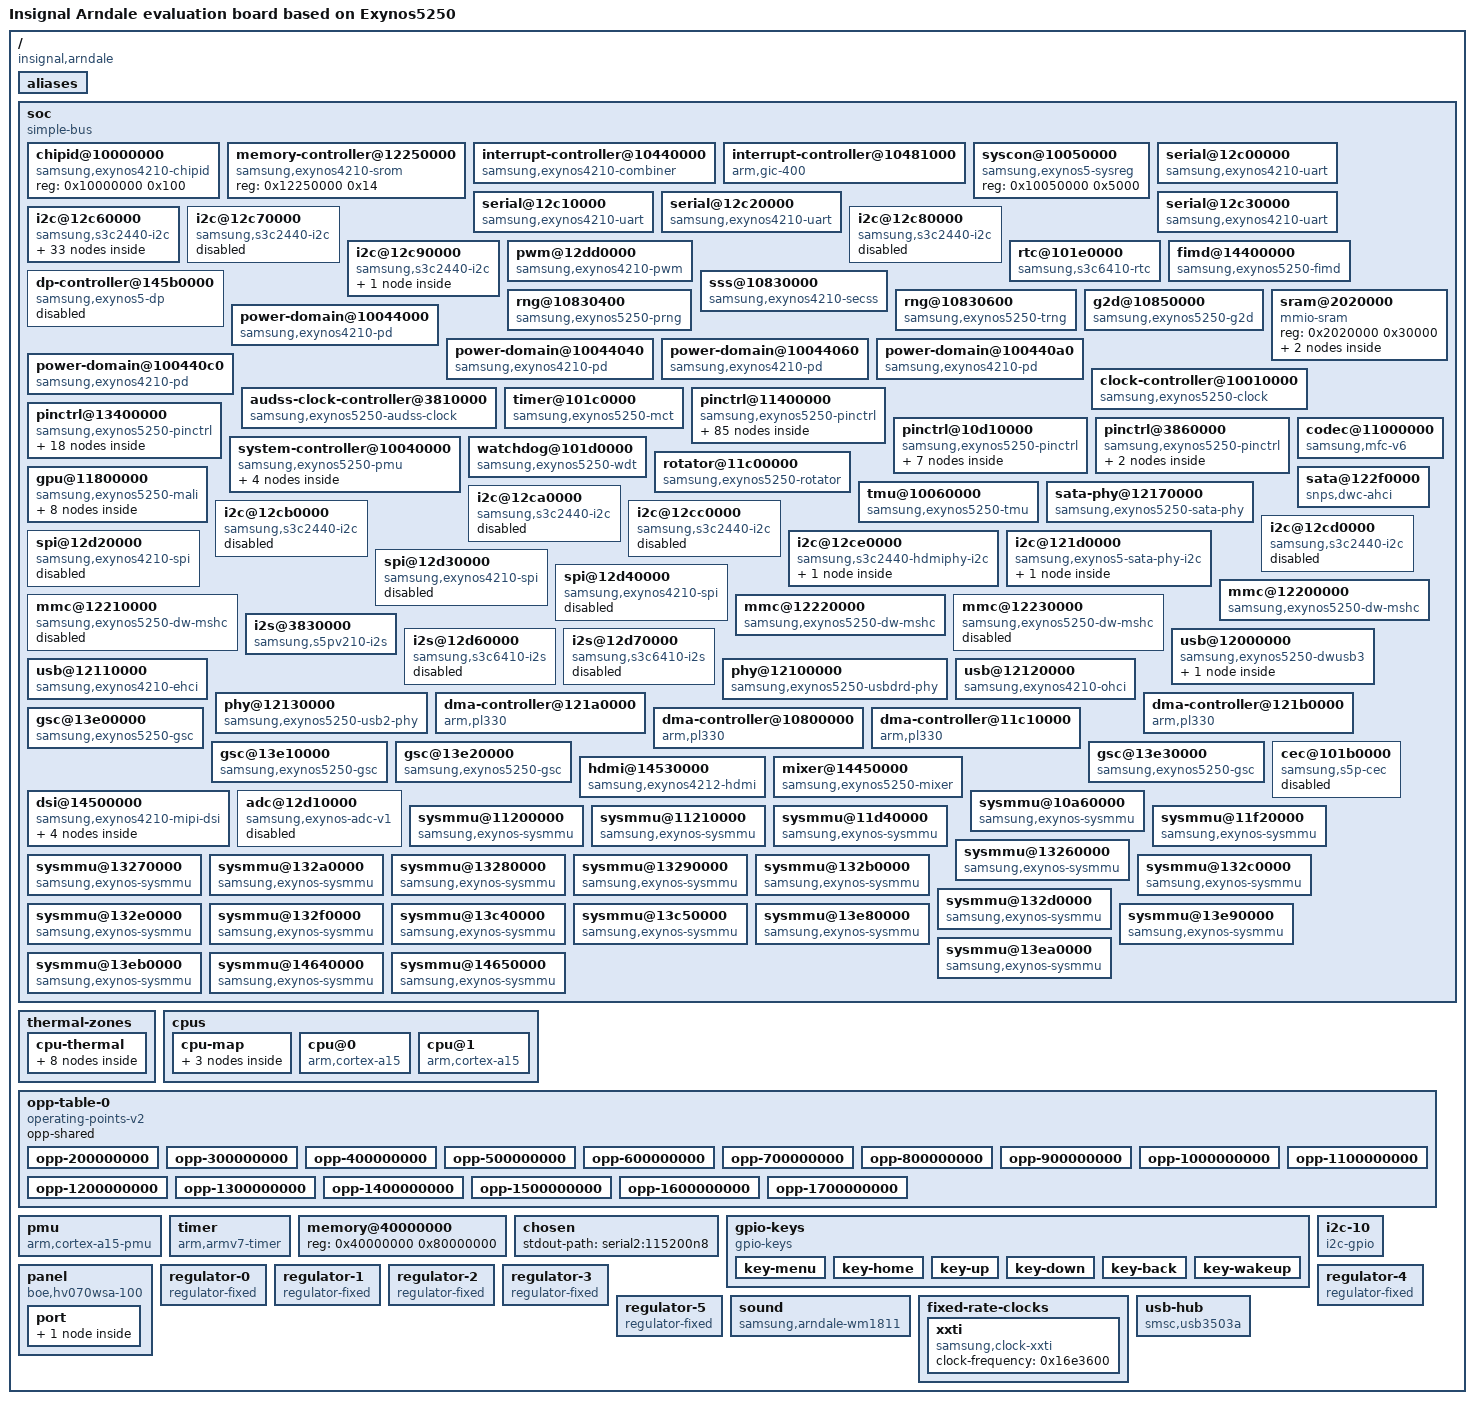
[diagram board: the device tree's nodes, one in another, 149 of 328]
/*
 * Copyright Linux Kernel Team
 *
 * SPDX-License-Identifier: GPL-2.0-only
 *
 * This file is derived from an intermediate build stage of the
 * Linux kernel. The licenses of all input files to this process
 * are compatible with GPL-2.0-only.
 */

/dts-v1/;

/ {
	interrupt-parent = <0x01>;
	#address-cells = <0x01>;
	#size-cells = <0x01>;
	compatible = "insignal,arndale", "samsung,exynos5250", "samsung,exynos5";
	model = "Insignal Arndale evaluation board based on Exynos5250";

	aliases {
		i2c0 = "/soc/i2c@12c60000";
		i2c1 = "/soc/i2c@12c70000";
		i2c2 = "/soc/i2c@12c80000";
		i2c3 = "/soc/i2c@12c90000";
		serial0 = "/soc/serial@12c00000";
		serial1 = "/soc/serial@12c10000";
		serial2 = "/soc/serial@12c20000";
		serial3 = "/soc/serial@12c30000";
		spi0 = "/soc/spi@12d20000";
		spi1 = "/soc/spi@12d30000";
		spi2 = "/soc/spi@12d40000";
		gsc0 = "/soc/gsc@13e00000";
		gsc1 = "/soc/gsc@13e10000";
		gsc2 = "/soc/gsc@13e20000";
		gsc3 = "/soc/gsc@13e30000";
		i2c4 = "/soc/i2c@12ca0000";
		i2c5 = "/soc/i2c@12cb0000";
		i2c6 = "/soc/i2c@12cc0000";
		i2c7 = "/soc/i2c@12cd0000";
		i2c8 = "/soc/i2c@12ce0000";
		i2c9 = "/soc/i2c@121d0000";
		pinctrl0 = "/soc/pinctrl@11400000";
		pinctrl1 = "/soc/pinctrl@13400000";
		pinctrl2 = "/soc/pinctrl@10d10000";
		pinctrl3 = "/soc/pinctrl@3860000";
		mmc0 = "/soc/mmc@12200000";
		mmc1 = "/soc/mmc@12220000";
	};

	soc {
		compatible = "simple-bus";
		#address-cells = <0x01>;
		#size-cells = <0x01>;
		ranges;

		chipid@10000000 {
			compatible = "samsung,exynos4210-chipid";
			reg = <0x10000000 0x100>;
		};

		memory-controller@12250000 {
			compatible = "samsung,exynos4210-srom";
			reg = <0x12250000 0x14>;
		};

		interrupt-controller@10440000 {
			compatible = "samsung,exynos4210-combiner";
			#interrupt-cells = <0x02>;
			interrupt-controller;
			samsung,combiner-nr = <0x20>;
			reg = <0x10440000 0x1000>;
			interrupts = <0x00 0x00 0x04 0x00 0x01 0x04 0x00 0x02 0x04 0x00 0x03 0x04 0x00 0x04 0x04 0x00 0x05 0x04 0x00 0x06 0x04 0x00 0x07 0x04 0x00 0x08 0x04 0x00 0x09 0x04 0x00 0x0a 0x04 0x00 0x0b 0x04 0x00 0x0c 0x04 0x00 0x0d 0x04 0x00 0x0e 0x04 0x00 0x0f 0x04 0x00 0x10 0x04 0x00 0x11 0x04 0x00 0x12 0x04 0x00 0x13 0x04 0x00 0x14 0x04 0x00 0x15 0x04 0x00 0x16 0x04 0x00 0x17 0x04 0x00 0x18 0x04 0x00 0x19 0x04 0x00 0x1a 0x04 0x00 0x1b 0x04 0x00 0x1c 0x04 0x00 0x1d 0x04 0x00 0x1e 0x04 0x00 0x1f 0x04>;
			phandle = <0x15>;
		};

		interrupt-controller@10481000 {
			compatible = "arm,gic-400", "arm,cortex-a15-gic";
			#interrupt-cells = <0x03>;
			interrupt-controller;
			reg = <0x10481000 0x1000 0x10482000 0x2000 0x10484000 0x2000 0x10486000 0x2000>;
			interrupts = <0x01 0x09 0xf04>;
			phandle = <0x01>;
		};

		syscon@10050000 {
			compatible = "samsung,exynos5-sysreg", "syscon";
			reg = <0x10050000 0x5000>;
			phandle = <0x05>;
		};

		serial@12c00000 {
			compatible = "samsung,exynos4210-uart";
			reg = <0x12c00000 0x100>;
			interrupts = <0x00 0x33 0x04>;
			clocks = <0x02 0x121 0x02 0x92>;
			clock-names = "uart", "clk_uart_baud0";
			dmas = <0x03 0x0d 0x03 0x0e>;
			dma-names = "rx", "tx";
		};

		serial@12c10000 {
			compatible = "samsung,exynos4210-uart";
			reg = <0x12c10000 0x100>;
			interrupts = <0x00 0x34 0x04>;
			clocks = <0x02 0x122 0x02 0x93>;
			clock-names = "uart", "clk_uart_baud0";
			dmas = <0x04 0x0f 0x04 0x10>;
			dma-names = "rx", "tx";
		};

		serial@12c20000 {
			compatible = "samsung,exynos4210-uart";
			reg = <0x12c20000 0x100>;
			interrupts = <0x00 0x35 0x04>;
			clocks = <0x02 0x123 0x02 0x94>;
			clock-names = "uart", "clk_uart_baud0";
			dmas = <0x03 0x0f 0x03 0x10>;
			dma-names = "rx", "tx";
		};

		serial@12c30000 {
			compatible = "samsung,exynos4210-uart";
			reg = <0x12c30000 0x100>;
			interrupts = <0x00 0x36 0x04>;
			clocks = <0x02 0x124 0x02 0x95>;
			clock-names = "uart", "clk_uart_baud0";
			dmas = <0x04 0x11 0x04 0x12>;
			dma-names = "rx", "tx";
		};

		i2c@12c60000 {
			compatible = "samsung,s3c2440-i2c";
			reg = <0x12c60000 0x100>;
			interrupts = <0x00 0x38 0x04>;
			#address-cells = <0x01>;
			#size-cells = <0x00>;
			samsung,sysreg-phandle = <0x05>;
			status = "okay";
			clocks = <0x02 0x126>;
			clock-names = "i2c";
			pinctrl-names = "default";
			pinctrl-0 = <0x06>;
			samsung,i2c-sda-delay = <0x64>;
			samsung,i2c-max-bus-freq = <0x4e20>;
			samsung,i2c-slave-addr = <0x66>;

			pmic@66 {
				compatible = "samsung,s5m8767-pmic";
				reg = <0x66>;
				interrupt-parent = <0x07>;
				interrupts = <0x02 0x08>;
				pinctrl-names = "default";
				pinctrl-0 = <0x08>;
				wakeup-source;
				vinb1-supply = <0x09>;
				vinb2-supply = <0x09>;
				vinb3-supply = <0x09>;
				vinb4-supply = <0x09>;
				vinb5-supply = <0x09>;
				vinb6-supply = <0x09>;
				vinb7-supply = <0x09>;
				vinb8-supply = <0x09>;
				vinb9-supply = <0x09>;
				vinl1-supply = <0x0a>;
				vinl2-supply = <0x0a>;
				vinl3-supply = <0x0a>;
				vinl4-supply = <0x09>;
				vinl5-supply = <0x09>;
				vinl6-supply = <0x09>;
				vinl7-supply = <0x09>;
				vinl8-supply = <0x0b>;
				vinl9-supply = <0x0b>;
				s5m8767,pmic-buck-dvs-gpios = <0x0c 0x00 0x00 0x0c 0x01 0x00 0x0c 0x02 0x00>;
				s5m8767,pmic-buck-ds-gpios = <0x0d 0x03 0x00 0x0d 0x04 0x00 0x0d 0x05 0x00>;

				clocks {
					compatible = "samsung,s5m8767-clk";
					#clock-cells = <0x01>;
					clock-output-names = "s5m8767_ap", "unused1", "unused2";
					phandle = <0x13>;
				};

				regulators {

					LDO1 {
						regulator-name = "VDD_ALIVE_1.0V";
						regulator-min-microvolt = <0x10c8e0>;
						regulator-max-microvolt = <0x10c8e0>;
						regulator-always-on;
						regulator-boot-on;
						op_mode = <0x01>;
					};

					LDO2 {
						regulator-name = "VDD_28IO_DP_1.35V";
						regulator-min-microvolt = <0x124f80>;
						regulator-max-microvolt = <0x124f80>;
						regulator-always-on;
						regulator-boot-on;
						op_mode = <0x01>;
					};

					LDO3 {
						regulator-name = "VDD_COMMON1_1.8V";
						regulator-min-microvolt = <0x1b7740>;
						regulator-max-microvolt = <0x1b7740>;
						regulator-always-on;
						regulator-boot-on;
						op_mode = <0x01>;
					};

					LDO4 {
						regulator-name = "VDD_IOPERI_1.8V";
						regulator-min-microvolt = <0x1b7740>;
						regulator-max-microvolt = <0x1b7740>;
						regulator-always-on;
						op_mode = <0x01>;
					};

					LDO5 {
						regulator-name = "VDD_EXT_1.8V";
						regulator-min-microvolt = <0x1b7740>;
						regulator-max-microvolt = <0x1b7740>;
						regulator-always-on;
						regulator-boot-on;
						op_mode = <0x01>;
					};

					LDO6 {
						regulator-name = "VDD_MPLL_1.1V";
						regulator-min-microvolt = <0x10c8e0>;
						regulator-max-microvolt = <0x10c8e0>;
						regulator-always-on;
						regulator-boot-on;
						op_mode = <0x01>;
					};

					LDO7 {
						regulator-name = "VDD_XPLL_1.1V";
						regulator-min-microvolt = <0x10c8e0>;
						regulator-max-microvolt = <0x10c8e0>;
						regulator-always-on;
						regulator-boot-on;
						op_mode = <0x01>;
					};

					LDO8 {
						regulator-name = "VDD_COMMON2_1.0V";
						regulator-min-microvolt = <0xf4240>;
						regulator-max-microvolt = <0xf4240>;
						regulator-always-on;
						regulator-boot-on;
						op_mode = <0x01>;
						phandle = <0x45>;
					};

					LDO9 {
						regulator-name = "VDD_33ON_3.0V";
						regulator-min-microvolt = <0x2dc6c0>;
						regulator-max-microvolt = <0x2dc6c0>;
						op_mode = <0x01>;
					};

					LDO10 {
						regulator-name = "VDD_COMMON3_1.8V";
						regulator-min-microvolt = <0x1b7740>;
						regulator-max-microvolt = <0x1b7740>;
						regulator-always-on;
						regulator-boot-on;
						op_mode = <0x01>;
						phandle = <0x44>;
					};

					LDO11 {
						regulator-name = "VDD_ABB2_1.8V";
						regulator-min-microvolt = <0x1b7740>;
						regulator-max-microvolt = <0x1b7740>;
						regulator-always-on;
						regulator-boot-on;
						op_mode = <0x01>;
					};

					LDO12 {
						regulator-name = "VDD_USB_3.0V";
						regulator-min-microvolt = <0x2dc6c0>;
						regulator-max-microvolt = <0x2dc6c0>;
						regulator-always-on;
						regulator-boot-on;
						op_mode = <0x01>;
						phandle = <0x39>;
					};

					LDO13 {
						regulator-name = "VDDQ_C2C_W_1.8V";
						regulator-min-microvolt = <0x1b7740>;
						regulator-max-microvolt = <0x1b7740>;
						regulator-always-on;
						regulator-boot-on;
						op_mode = <0x01>;
					};

					LDO14 {
						regulator-name = "VDD18_ABB0_3_1.8V";
						regulator-min-microvolt = <0x1b7740>;
						regulator-max-microvolt = <0x1b7740>;
						regulator-always-on;
						regulator-boot-on;
						op_mode = <0x01>;
					};

					LDO15 {
						regulator-name = "VDD10_COMMON4_1.0V";
						regulator-min-microvolt = <0xf4240>;
						regulator-max-microvolt = <0xf4240>;
						regulator-always-on;
						regulator-boot-on;
						op_mode = <0x01>;
						phandle = <0x38>;
					};

					LDO16 {
						regulator-name = "VDD18_HSIC_1.8V";
						regulator-min-microvolt = <0x1b7740>;
						regulator-max-microvolt = <0x1b7740>;
						regulator-always-on;
						regulator-boot-on;
						op_mode = <0x01>;
					};

					LDO17 {
						regulator-name = "VDDQ_MMC2_3_2.8V";
						regulator-min-microvolt = <0x2ab980>;
						regulator-max-microvolt = <0x2ab980>;
						regulator-always-on;
						regulator-boot-on;
						op_mode = <0x01>;
					};

					LDO18 {
						regulator-name = "VDD_33ON_2.8V";
						regulator-min-microvolt = <0x2ab980>;
						regulator-max-microvolt = <0x2ab980>;
						op_mode = <0x01>;
					};

					LDO22 {
						regulator-name = "EXT_33_OFF";
						regulator-min-microvolt = <0x325aa0>;
						regulator-max-microvolt = <0x325aa0>;
						op_mode = <0x01>;
					};

					LDO23 {
						regulator-name = "EXT_28_OFF";
						regulator-min-microvolt = <0x2ab980>;
						regulator-max-microvolt = <0x2ab980>;
						op_mode = <0x01>;
					};

					LDO25 {
						regulator-name = "PVDD_LDO25";
						regulator-min-microvolt = <0x124f80>;
						regulator-max-microvolt = <0x124f80>;
						op_mode = <0x01>;
					};

					LDO26 {
						regulator-name = "EXT_18_OFF";
						regulator-min-microvolt = <0x1b7740>;
						regulator-max-microvolt = <0x1b7740>;
						op_mode = <0x01>;
					};

					BUCK1 {
						regulator-name = "VDD_MIF";
						regulator-min-microvolt = <0xe7ef0>;
						regulator-max-microvolt = <0x124f80>;
						regulator-always-on;
						regulator-boot-on;
						op_mode = <0x01>;
					};

					BUCK2 {
						regulator-name = "VDD_ARM";
						regulator-min-microvolt = <0xdec74>;
						regulator-max-microvolt = <0x13d620>;
						regulator-always-on;
						regulator-boot-on;
						op_mode = <0x01>;
						phandle = <0x54>;
					};

					BUCK3 {
						regulator-name = "VDD_INT";
						regulator-min-microvolt = <0xdbba0>;
						regulator-max-microvolt = <0x124f80>;
						regulator-always-on;
						regulator-boot-on;
						op_mode = <0x01>;
					};

					BUCK4 {
						regulator-name = "VDD_G3D";
						regulator-min-microvolt = <0xcf850>;
						regulator-max-microvolt = <0x13d620>;
						regulator-always-on;
						regulator-boot-on;
						op_mode = <0x01>;
						phandle = <0x22>;
					};

					BUCK5 {
						regulator-name = "VDD_MEM_1.35V";
						regulator-min-microvolt = <0xb71b0>;
						regulator-max-microvolt = <0x14acf8>;
						regulator-always-on;
						regulator-boot-on;
						op_mode = <0x01>;
					};

					BUCK7 {
						regulator-name = "PVDD_BUCK7";
						regulator-always-on;
						op_mode = <0x01>;
						phandle = <0x0a>;
					};

					BUCK8 {
						regulator-name = "PVDD_BUCK8";
						regulator-always-on;
						op_mode = <0x01>;
						phandle = <0x0b>;
					};

					BUCK9 {
						regulator-name = "VDD_33_OFF_EXT1";
						regulator-min-microvolt = <0xb71b0>;
						regulator-max-microvolt = <0x2dc6c0>;
						op_mode = <0x01>;
					};
				};
			};
		};

		i2c@12c70000 {
			compatible = "samsung,s3c2440-i2c";
			reg = <0x12c70000 0x100>;
			interrupts = <0x00 0x39 0x04>;
			#address-cells = <0x01>;
			#size-cells = <0x00>;
			samsung,sysreg-phandle = <0x05>;
			status = "disabled";
			clocks = <0x02 0x127>;
			clock-names = "i2c";
			pinctrl-names = "default";
			pinctrl-0 = <0x0e>;
		};

		i2c@12c80000 {
			compatible = "samsung,s3c2440-i2c";
			reg = <0x12c80000 0x100>;
			interrupts = <0x00 0x3a 0x04>;
			#address-cells = <0x01>;
			#size-cells = <0x00>;
			samsung,sysreg-phandle = <0x05>;
			status = "disabled";
			clocks = <0x02 0x128>;
			clock-names = "i2c";
			pinctrl-names = "default";
			pinctrl-0 = <0x0f>;
		};

		i2c@12c90000 {
			compatible = "samsung,s3c2440-i2c";
			reg = <0x12c90000 0x100>;
			interrupts = <0x00 0x3b 0x04>;
			#address-cells = <0x01>;
			#size-cells = <0x00>;
			samsung,sysreg-phandle = <0x05>;
			status = "okay";
			clocks = <0x02 0x129>;
			clock-names = "i2c";
			pinctrl-names = "default";
			pinctrl-0 = <0x10>;

			audio-codec@1a {
				compatible = "wlf,wm1811";
				reg = <0x1a>;
				clocks = <0x11 0x00>;
				clock-names = "MCLK1";
				AVDD2-supply = <0x09>;
				CPVDD-supply = <0x09>;
				DBVDD1-supply = <0x09>;
				DBVDD2-supply = <0x09>;
				DBVDD3-supply = <0x09>;
				LDO1VDD-supply = <0x09>;
				SPKVDD1-supply = <0x09>;
				SPKVDD2-supply = <0x09>;
				wlf,ldo1ena-gpios = <0x12 0x00 0x00>;
				wlf,ldo2ena-gpios = <0x12 0x01 0x00>;
				phandle = <0x59>;
			};
		};

		pwm@12dd0000 {
			compatible = "samsung,exynos4210-pwm";
			reg = <0x12dd0000 0x100>;
			interrupts = <0x00 0x24 0x04 0x00 0x25 0x04 0x00 0x26 0x04 0x00 0x27 0x04 0x00 0x28 0x04>;
			samsung,pwm-outputs = <0x00 0x01 0x02 0x03>;
			#pwm-cells = <0x03>;
			clocks = <0x02 0x137>;
			clock-names = "timers";
		};

		rtc@101e0000 {
			compatible = "samsung,s3c6410-rtc";
			reg = <0x101e0000 0x100>;
			interrupts = <0x00 0x2b 0x04 0x00 0x2c 0x04>;
			status = "okay";
			clocks = <0x02 0x151 0x13 0x00>;
			clock-names = "rtc", "rtc_src";
			interrupt-parent = <0x14>;
		};

		fimd@14400000 {
			compatible = "samsung,exynos5250-fimd";
			interrupt-parent = <0x15>;
			reg = <0x14400000 0x40000>;
			interrupt-names = "fifo", "vsync", "lcd_sys";
			interrupts = <0x12 0x04 0x12 0x05 0x12 0x06>;
			samsung,sysreg = <0x05>;
			status = "okay";
			power-domains = <0x16>;
			clocks = <0x02 0x85 0x02 0x153>;
			clock-names = "sclk_fimd", "fimd";
			iommus = <0x17>;
		};

		dp-controller@145b0000 {
			compatible = "samsung,exynos5-dp";
			reg = <0x145b0000 0x1000>;
			interrupts = <0x0a 0x03>;
			interrupt-parent = <0x15>;
			status = "disabled";
			power-domains = <0x16>;
			clocks = <0x02 0x156>;
			clock-names = "dp";
			phys = <0x18>;
			phy-names = "dp";
		};

		sss@10830000 {
			compatible = "samsung,exynos4210-secss";
			reg = <0x10830000 0x300>;
			interrupts = <0x00 0x70 0x04>;
			clocks = <0x02 0x15c>;
			clock-names = "secss";
		};

		rng@10830400 {
			compatible = "samsung,exynos5250-prng";
			reg = <0x10830400 0x200>;
			clocks = <0x02 0x15c>;
			clock-names = "secss";
		};

		rng@10830600 {
			compatible = "samsung,exynos5250-trng";
			reg = <0x10830600 0x100>;
			clocks = <0x02 0x15c>;
			clock-names = "secss";
		};

		g2d@10850000 {
			compatible = "samsung,exynos5250-g2d";
			reg = <0x10850000 0x1000>;
			interrupts = <0x00 0x5b 0x04>;
			status = "okay";
			iommus = <0x19>;
			clocks = <0x02 0x159>;
			clock-names = "fimg2d";
		};

		sram@2020000 {
			compatible = "mmio-sram";
			reg = <0x2020000 0x30000>;
			#address-cells = <0x01>;
			#size-cells = <0x01>;
			ranges = <0x00 0x2020000 0x30000>;

			smp-sram@0 {
				compatible = "samsung,exynos4210-sysram";
				reg = <0x00 0x1000>;
			};

			smp-sram@2f000 {
				compatible = "samsung,exynos4210-sysram-ns";
				reg = <0x2f000 0x1000>;
			};
		};

		power-domain@10044000 {
			compatible = "samsung,exynos4210-pd";
			reg = <0x10044000 0x20>;
			#power-domain-cells = <0x00>;
			label = "GSC";
			phandle = <0x3c>;
		};

		power-domain@10044040 {
			compatible = "samsung,exynos4210-pd";
			reg = <0x10044040 0x20>;
			#power-domain-cells = <0x00>;
			label = "MFC";
			phandle = <0x1c>;
		};

		power-domain@10044060 {
			compatible = "samsung,exynos4210-pd";
			reg = <0x10044060 0x20>;
			#power-domain-cells = <0x00>;
			label = "G3D";
			phandle = <0x21>;
		};

		power-domain@100440a0 {
			compatible = "samsung,exynos4210-pd";
			reg = <0x100440a0 0x20>;
			#power-domain-cells = <0x00>;
			label = "DISP1";
			phandle = <0x16>;
		};

		power-domain@100440c0 {
			compatible = "samsung,exynos4210-pd";
			reg = <0x100440c0 0x20>;
			#power-domain-cells = <0x00>;
			label = "MAU";
			phandle = <0x1a>;
		};

		clock-controller@10010000 {
			compatible = "samsung,exynos5250-clock";
			reg = <0x10010000 0x30000>;
			#clock-cells = <0x01>;
			assigned-clocks = <0x02 0x07>;
			assigned-clock-rates = <0x2ee0000>;
			phandle = <0x02>;
		};

		audss-clock-controller@3810000 {
			compatible = "samsung,exynos5250-audss-clock";
			reg = <0x3810000 0x0c>;
			#clock-cells = <0x01>;
			clocks = <0x02 0x01 0x02 0x07 0x02 0x8a 0x02 0xa0>;
			clock-names = "pll_ref", "pll_in", "sclk_audio", "sclk_pcm_in";
			power-domains = <0x1a>;
			assigned-clocks = <0x1b 0x00>;
			assigned-clock-parents = <0x02 0x07>;
			phandle = <0x1b>;
		};

		timer@101c0000 {
			compatible = "samsung,exynos5250-mct", "samsung,exynos4210-mct";
			reg = <0x101c0000 0x800>;
			clocks = <0x02 0x01 0x02 0x14f>;
			clock-names = "fin_pll", "mct";
			interrupts-extended = <0x15 0x17 0x03 0x15 0x17 0x04 0x15 0x19 0x02 0x15 0x19 0x03 0x01 0x00 0x78 0x04 0x01 0x00 0x79 0x04>;
		};

		pinctrl@11400000 {
			compatible = "samsung,exynos5250-pinctrl";
			reg = <0x11400000 0x1000>;
			interrupts = <0x00 0x2e 0x04>;

			wakeup-interrupt-controller {
				compatible = "samsung,exynos4210-wakeup-eint";
				interrupt-parent = <0x01>;
				interrupts = <0x00 0x20 0x04>;
			};

			gpa0-gpio-bank {
				gpio-controller;
				#gpio-cells = <0x02>;
				interrupt-controller;
				#interrupt-cells = <0x02>;
				phandle = <0x57>;
			};

			gpa1-gpio-bank {
				gpio-controller;
				#gpio-cells = <0x02>;
				interrupt-controller;
				#interrupt-cells = <0x02>;
			};

			gpa2-gpio-bank {
				gpio-controller;
				#gpio-cells = <0x02>;
				interrupt-controller;
				#interrupt-cells = <0x02>;
			};

			gpb0-gpio-bank {
				gpio-controller;
				#gpio-cells = <0x02>;
				interrupt-controller;
				#interrupt-cells = <0x02>;
				phandle = <0x12>;
			};

			gpb1-gpio-bank {
				gpio-controller;
				#gpio-cells = <0x02>;
				interrupt-controller;
				#interrupt-cells = <0x02>;
			};

			gpb2-gpio-bank {
				gpio-controller;
				#gpio-cells = <0x02>;
				interrupt-controller;
				#interrupt-cells = <0x02>;
			};

			gpb3-gpio-bank {
				gpio-controller;
				#gpio-cells = <0x02>;
				interrupt-controller;
				#interrupt-cells = <0x02>;
			};

			gpc0-gpio-bank {
				gpio-controller;
				#gpio-cells = <0x02>;
				interrupt-controller;
				#interrupt-cells = <0x02>;
			};

			gpc1-gpio-bank {
				gpio-controller;
				#gpio-cells = <0x02>;
				interrupt-controller;
				#interrupt-cells = <0x02>;
			};

			gpc2-gpio-bank {
				gpio-controller;
				#gpio-cells = <0x02>;
				interrupt-controller;
				#interrupt-cells = <0x02>;
			};

			gpc3-gpio-bank {
				gpio-controller;
				#gpio-cells = <0x02>;
				interrupt-controller;
				#interrupt-cells = <0x02>;
			};

			gpd0-gpio-bank {
				gpio-controller;
				#gpio-cells = <0x02>;
				interrupt-controller;
				#interrupt-cells = <0x02>;
			};

			gpd1-gpio-bank {
				gpio-controller;
				#gpio-cells = <0x02>;
				interrupt-controller;
				#interrupt-cells = <0x02>;
				phandle = <0x0c>;
			};

			gpy0-gpio-bank {
				gpio-controller;
				#gpio-cells = <0x02>;
			};

			gpy1-gpio-bank {
				gpio-controller;
				#gpio-cells = <0x02>;
			};

			gpy2-gpio-bank {
				gpio-controller;
				#gpio-cells = <0x02>;
			};

			gpy3-gpio-bank {
				gpio-controller;
				#gpio-cells = <0x02>;
			};

			gpy4-gpio-bank {
				gpio-controller;
				#gpio-cells = <0x02>;
			};

			gpy5-gpio-bank {
				gpio-controller;
				#gpio-cells = <0x02>;
			};

			gpy6-gpio-bank {
				gpio-controller;
				#gpio-cells = <0x02>;
			};

			gpc4-gpio-bank {
				gpio-controller;
				#gpio-cells = <0x02>;
				interrupt-controller;
				#interrupt-cells = <0x02>;
			};

			gpx0-gpio-bank {
				gpio-controller;
				#gpio-cells = <0x02>;
				interrupt-controller;
				interrupt-parent = <0x15>;
				#interrupt-cells = <0x02>;
				interrupts = <0x17 0x00 0x18 0x00 0x19 0x00 0x19 0x01 0x1a 0x00 0x1a 0x01 0x1b 0x00 0x1b 0x01>;
			};

			gpx1-gpio-bank {
				gpio-controller;
				#gpio-cells = <0x02>;
				interrupt-controller;
				interrupt-parent = <0x15>;
				#interrupt-cells = <0x02>;
				interrupts = <0x1c 0x00 0x1c 0x01 0x1d 0x00 0x1d 0x01 0x1e 0x00 0x1e 0x01 0x1f 0x00 0x1f 0x01>;
				phandle = <0x55>;
			};

			gpx2-gpio-bank {
				gpio-controller;
				#gpio-cells = <0x02>;
				interrupt-controller;
				#interrupt-cells = <0x02>;
				phandle = <0x0d>;
			};

			gpx3-gpio-bank {
				gpio-controller;
				#gpio-cells = <0x02>;
				interrupt-controller;
				#interrupt-cells = <0x02>;
				phandle = <0x07>;
			};

			uart0-data-pins {
				samsung,pins = "gpa0-0", "gpa0-1";
				samsung,pin-function = <0x02>;
				samsung,pin-pud = <0x00>;
				samsung,pin-drv = <0x00>;
			};

			uart0-fctl-pins {
				samsung,pins = "gpa0-2", "gpa0-3";
				samsung,pin-function = <0x02>;
				samsung,pin-pud = <0x00>;
				samsung,pin-drv = <0x00>;
			};

			i2c2-bus-pins {
				samsung,pins = "gpa0-6", "gpa0-7";
				samsung,pin-function = <0x03>;
				samsung,pin-pud = <0x03>;
				samsung,pin-drv = <0x00>;
				phandle = <0x0f>;
			};

			i2c2-hs-bus-pins {
				samsung,pins = "gpa0-6", "gpa0-7";
				samsung,pin-function = <0x04>;
				samsung,pin-pud = <0x03>;
				samsung,pin-drv = <0x00>;
			};

			i2c2-gpio-bus-pins {
				samsung,pins = "gpa0-6", "gpa0-7";
				samsung,pin-pud = <0x00>;
				samsung,pin-drv = <0x00>;
				phandle = <0x56>;
			};

			uart2-data-pins {
				samsung,pins = "gpa1-0", "gpa1-1";
				samsung,pin-function = <0x02>;
				samsung,pin-pud = <0x00>;
				samsung,pin-drv = <0x00>;
			};

			uart2-fctl-pins {
				samsung,pins = "gpa1-2", "gpa1-3";
				samsung,pin-function = <0x02>;
				samsung,pin-pud = <0x00>;
				samsung,pin-drv = <0x00>;
			};

			i2c3-bus-pins {
				samsung,pins = "gpa1-2", "gpa1-3";
				samsung,pin-function = <0x03>;
				samsung,pin-pud = <0x03>;
				samsung,pin-drv = <0x00>;
				phandle = <0x10>;
			};

			i2c3-hs-bus-pins {
				samsung,pins = "gpa1-2", "gpa1-3";
				samsung,pin-function = <0x04>;
				samsung,pin-pud = <0x03>;
				samsung,pin-drv = <0x00>;
			};

			uart3-data-pins {
				samsung,pins = "gpa1-4", "gpa1-5";
				samsung,pin-function = <0x02>;
				samsung,pin-pud = <0x00>;
				samsung,pin-drv = <0x00>;
			};

			spi0-bus-pins {
				samsung,pins = "gpa2-0", "gpa2-2", "gpa2-3";
				samsung,pin-function = <0x02>;
				samsung,pin-pud = <0x03>;
				samsung,pin-drv = <0x00>;
				phandle = <0x29>;
			};

			i2c4-bus-pins {
				samsung,pins = "gpa2-0", "gpa2-1";
				samsung,pin-function = <0x03>;
				samsung,pin-pud = <0x03>;
				samsung,pin-drv = <0x00>;
				phandle = <0x25>;
			};

			i2c5-bus-pins {
				samsung,pins = "gpa2-2", "gpa2-3";
				samsung,pin-function = <0x03>;
				samsung,pin-pud = <0x03>;
				samsung,pin-drv = <0x00>;
				phandle = <0x26>;
			};

			spi1-bus-pins {
				samsung,pins = "gpa2-4", "gpa2-6", "gpa2-7";
				samsung,pin-function = <0x02>;
				samsung,pin-pud = <0x03>;
				samsung,pin-drv = <0x00>;
				phandle = <0x2a>;
			};

			i2s1-bus-pins {
				samsung,pins = "gpb0-0", "gpb0-1", "gpb0-2", "gpb0-3", "gpb0-4";
				samsung,pin-function = <0x02>;
				samsung,pin-pud = <0x00>;
				samsung,pin-drv = <0x00>;
				phandle = <0x36>;
			};

			pcm1-bus-pins {
				samsung,pins = "gpb0-0", "gpb0-1", "gpb0-2", "gpb0-3", "gpb0-4";
				samsung,pin-function = <0x03>;
				samsung,pin-pud = <0x00>;
				samsung,pin-drv = <0x00>;
			};

			ac97-bus-pins {
				samsung,pins = "gpb0-0", "gpb0-1", "gpb0-2", "gpb0-3", "gpb0-4";
				samsung,pin-function = <0x04>;
				samsung,pin-pud = <0x00>;
				samsung,pin-drv = <0x00>;
			};

			i2s2-bus-pins {
				samsung,pins = "gpb1-0", "gpb1-1", "gpb1-2", "gpb1-3", "gpb1-4";
				samsung,pin-function = <0x02>;
				samsung,pin-pud = <0x00>;
				samsung,pin-drv = <0x00>;
				phandle = <0x37>;
			};

			pcm2-bus-pins {
				samsung,pins = "gpb1-0", "gpb1-1", "gpb1-2", "gpb1-3", "gpb1-4";
				samsung,pin-function = <0x03>;
				samsung,pin-pud = <0x00>;
				samsung,pin-drv = <0x00>;
			};

			spdif-bus-pins {
				samsung,pins = "gpb1-0", "gpb1-1";
				samsung,pin-function = <0x04>;
				samsung,pin-pud = <0x00>;
				samsung,pin-drv = <0x00>;
			};

			spi2-bus-pins {
				samsung,pins = "gpb1-1", "gpb1-3", "gpb1-4";
				samsung,pin-function = <0x05>;
				samsung,pin-pud = <0x03>;
				samsung,pin-drv = <0x00>;
				phandle = <0x2b>;
			};

			i2c6-bus-pins {
				samsung,pins = "gpb1-3", "gpb1-4";
				samsung,pin-function = <0x04>;
				samsung,pin-pud = <0x03>;
				samsung,pin-drv = <0x00>;
				phandle = <0x27>;
			};

			pwm0-out-pins {
				samsung,pins = "gpb2-0";
				samsung,pin-function = <0x02>;
				samsung,pin-pud = <0x00>;
				samsung,pin-drv = <0x00>;
			};

			pwm1-out-pins {
				samsung,pins = "gpb2-1";
				samsung,pin-function = <0x02>;
				samsung,pin-pud = <0x00>;
				samsung,pin-drv = <0x00>;
			};

			pwm2-out-pins {
				samsung,pins = "gpb2-2";
				samsung,pin-function = <0x02>;
				samsung,pin-pud = <0x00>;
				samsung,pin-drv = <0x00>;
			};

			pwm3-out-pins {
				samsung,pins = "gpb2-3";
				samsung,pin-function = <0x02>;
				samsung,pin-pud = <0x00>;
				samsung,pin-drv = <0x00>;
			};

			i2c7-bus-pins {
				samsung,pins = "gpb2-2", "gpb2-3";
				samsung,pin-function = <0x03>;
				samsung,pin-pud = <0x03>;
				samsung,pin-drv = <0x00>;
				phandle = <0x28>;
			};

			i2c0-bus-pins {
				samsung,pins = "gpb3-0", "gpb3-1";
				samsung,pin-function = <0x02>;
				samsung,pin-pud = <0x03>;
				samsung,pin-drv = <0x00>;
				phandle = <0x06>;
			};

			i2c1-bus-pins {
				samsung,pins = "gpb3-2", "gpb3-3";
				samsung,pin-function = <0x02>;
				samsung,pin-pud = <0x03>;
				samsung,pin-drv = <0x00>;
				phandle = <0x0e>;
			};

			i2c0-hs-bus-pins {
				samsung,pins = "gpb3-0", "gpb3-1";
				samsung,pin-function = <0x04>;
				samsung,pin-pud = <0x03>;
				samsung,pin-drv = <0x00>;
			};

			i2c1-hs-bus-pins {
				samsung,pins = "gpb3-2", "gpb3-3";
				samsung,pin-function = <0x04>;
				samsung,pin-pud = <0x03>;
				samsung,pin-drv = <0x00>;
			};

			sd0-clk-pins {
				samsung,pins = "gpc0-0";
				samsung,pin-function = <0x02>;
				samsung,pin-pud = <0x00>;
				samsung,pin-drv = <0x03>;
				phandle = <0x2d>;
			};

			sd0-cmd-pins {
				samsung,pins = "gpc0-1";
				samsung,pin-function = <0x02>;
				samsung,pin-pud = <0x00>;
				samsung,pin-drv = <0x03>;
				phandle = <0x2e>;
			};

			sd0-cd-pins {
				samsung,pins = "gpc0-2";
				samsung,pin-function = <0x02>;
				samsung,pin-pud = <0x03>;
				samsung,pin-drv = <0x03>;
			};

			sd0-bus-width1-pins {
				samsung,pins = "gpc0-3";
				samsung,pin-function = <0x02>;
				samsung,pin-pud = <0x03>;
				samsung,pin-drv = <0x03>;
			};

			sd0-bus-width4-pins {
				samsung,pins = "gpc0-3", "gpc0-4", "gpc0-5", "gpc0-6";
				samsung,pin-function = <0x02>;
				samsung,pin-pud = <0x03>;
				samsung,pin-drv = <0x03>;
				phandle = <0x2f>;
			};

			sd0-bus-width8-pins {
				samsung,pins = "gpc1-0", "gpc1-1", "gpc1-2", "gpc1-3";
				samsung,pin-function = <0x02>;
				samsung,pin-pud = <0x03>;
				samsung,pin-drv = <0x03>;
				phandle = <0x30>;
			};

			sd1-clk-pins {
				samsung,pins = "gpc2-0";
				samsung,pin-function = <0x02>;
				samsung,pin-pud = <0x00>;
				samsung,pin-drv = <0x03>;
			};

			sd1-cmd-pins {
				samsung,pins = "gpc2-1";
				samsung,pin-function = <0x02>;
				samsung,pin-pud = <0x00>;
				samsung,pin-drv = <0x03>;
			};

			sd1-cd-pins {
				samsung,pins = "gpc2-2";
				samsung,pin-function = <0x02>;
				samsung,pin-pud = <0x03>;
				samsung,pin-drv = <0x03>;
			};

			sd1-bus-width1-pins {
				samsung,pins = "gpc2-3";
				samsung,pin-function = <0x02>;
				samsung,pin-pud = <0x03>;
				samsung,pin-drv = <0x03>;
			};

			sd1-bus-width4-pins {
				samsung,pins = "gpc2-3", "gpc2-4", "gpc2-5", "gpc2-6";
				samsung,pin-function = <0x02>;
				samsung,pin-pud = <0x03>;
				samsung,pin-drv = <0x03>;
			};

			sd2-clk-pins {
				samsung,pins = "gpc3-0";
				samsung,pin-function = <0x02>;
				samsung,pin-pud = <0x00>;
				samsung,pin-drv = <0x03>;
				phandle = <0x31>;
			};

			sd2-cmd-pins {
				samsung,pins = "gpc3-1";
				samsung,pin-function = <0x02>;
				samsung,pin-pud = <0x00>;
				samsung,pin-drv = <0x03>;
				phandle = <0x32>;
			};

			sd2-cd-pins {
				samsung,pins = "gpc3-2";
				samsung,pin-function = <0x02>;
				samsung,pin-pud = <0x03>;
				samsung,pin-drv = <0x03>;
				phandle = <0x33>;
			};

			sd2-bus-width1-pins {
				samsung,pins = "gpc3-3";
				samsung,pin-function = <0x02>;
				samsung,pin-pud = <0x03>;
				samsung,pin-drv = <0x03>;
			};

			sd2-bus-width4-pins {
				samsung,pins = "gpc3-3", "gpc3-4", "gpc3-5", "gpc3-6";
				samsung,pin-function = <0x02>;
				samsung,pin-pud = <0x03>;
				samsung,pin-drv = <0x03>;
				phandle = <0x34>;
			};

			sd2-bus-width8-pins {
				samsung,pins = "gpc4-3", "gpc4-4", "gpc4-5", "gpc4-6";
				samsung,pin-function = <0x03>;
				samsung,pin-pud = <0x03>;
				samsung,pin-drv = <0x03>;
			};

			sd3-clk-pins {
				samsung,pins = "gpc4-0";
				samsung,pin-function = <0x02>;
				samsung,pin-pud = <0x00>;
				samsung,pin-drv = <0x03>;
			};

			sd3-cmd-pins {
				samsung,pins = "gpc4-1";
				samsung,pin-function = <0x02>;
				samsung,pin-pud = <0x00>;
				samsung,pin-drv = <0x03>;
			};

			sd3-cd-pins {
				samsung,pins = "gpc4-2";
				samsung,pin-function = <0x02>;
				samsung,pin-pud = <0x03>;
				samsung,pin-drv = <0x03>;
			};

			sd3-bus-width1-pins {
				samsung,pins = "gpc4-3";
				samsung,pin-function = <0x02>;
				samsung,pin-pud = <0x03>;
				samsung,pin-drv = <0x03>;
			};

			sd3-bus-width4-pins {
				samsung,pins = "gpc4-3", "gpc4-4", "gpc4-5", "gpc4-6";
				samsung,pin-function = <0x02>;
				samsung,pin-pud = <0x03>;
				samsung,pin-drv = <0x03>;
			};

			uart1-data-pins {
				samsung,pins = "gpd0-0", "gpd0-1";
				samsung,pin-function = <0x02>;
				samsung,pin-pud = <0x00>;
				samsung,pin-drv = <0x00>;
			};

			uart1-fctl-pins {
				samsung,pins = "gpd0-2", "gpd0-3";
				samsung,pin-function = <0x02>;
				samsung,pin-pud = <0x00>;
				samsung,pin-drv = <0x00>;
			};

			dp-hpd-pins {
				samsung,pins = "gpx0-7";
				samsung,pin-function = <0x03>;
				samsung,pin-pud = <0x00>;
				samsung,pin-drv = <0x00>;
			};

			hdmi-cec-pins {
				samsung,pins = "gpx3-6";
				samsung,pin-function = <0x03>;
				samsung,pin-pud = <0x00>;
				samsung,pin-drv = <0x00>;
				phandle = <0x47>;
			};

			hdmi-hpd-pins {
				samsung,pins = "gpx3-7";
				samsung,pin-pud = <0x00>;
				phandle = <0x42>;
			};

			s5m8767-irq-pins {
				samsung,pins = "gpx3-2";
				samsung,pin-pud = <0x00>;
				phandle = <0x08>;
			};
		};

		pinctrl@13400000 {
			compatible = "samsung,exynos5250-pinctrl";
			reg = <0x13400000 0x1000>;
			interrupts = <0x00 0x2d 0x04>;

			gpe0-gpio-bank {
				gpio-controller;
				#gpio-cells = <0x02>;
				interrupt-controller;
				#interrupt-cells = <0x02>;
			};

			gpe1-gpio-bank {
				gpio-controller;
				#gpio-cells = <0x02>;
				interrupt-controller;
				#interrupt-cells = <0x02>;
			};

			gpf0-gpio-bank {
				gpio-controller;
				#gpio-cells = <0x02>;
				interrupt-controller;
				#interrupt-cells = <0x02>;
			};

			gpf1-gpio-bank {
				gpio-controller;
				#gpio-cells = <0x02>;
				interrupt-controller;
				#interrupt-cells = <0x02>;
			};

			gpg0-gpio-bank {
				gpio-controller;
				#gpio-cells = <0x02>;
				interrupt-controller;
				#interrupt-cells = <0x02>;
			};

			gpg1-gpio-bank {
				gpio-controller;
				#gpio-cells = <0x02>;
				interrupt-controller;
				#interrupt-cells = <0x02>;
			};

			gpg2-gpio-bank {
				gpio-controller;
				#gpio-cells = <0x02>;
				interrupt-controller;
				#interrupt-cells = <0x02>;
			};

			gph0-gpio-bank {
				gpio-controller;
				#gpio-cells = <0x02>;
				interrupt-controller;
				#interrupt-cells = <0x02>;
			};

			gph1-gpio-bank {
				gpio-controller;
				#gpio-cells = <0x02>;
				interrupt-controller;
				#interrupt-cells = <0x02>;
			};

			cam-gpio-a-pins {
				samsung,pins = "gpe0-0", "gpe0-1", "gpe0-2", "gpe0-3", "gpe0-4", "gpe0-5", "gpe0-6", "gpe0-7", "gpe1-0", "gpe1-1";
				samsung,pin-function = <0x02>;
				samsung,pin-pud = <0x00>;
				samsung,pin-drv = <0x00>;
			};

			cam-gpio-b-pins {
				samsung,pins = "gpf0-0", "gpf0-1", "gpf0-2", "gpf0-3", "gpf1-0", "gpf1-1", "gpf1-2", "gpf1-3";
				samsung,pin-function = <0x03>;
				samsung,pin-pud = <0x00>;
				samsung,pin-drv = <0x00>;
			};

			cam-i2c2-bus-pins {
				samsung,pins = "gpe0-6", "gpe1-0";
				samsung,pin-function = <0x04>;
				samsung,pin-pud = <0x03>;
				samsung,pin-drv = <0x00>;
			};

			cam-spi1-bus-pins {
				samsung,pins = "gpe0-4", "gpe0-5", "gpf0-2", "gpf0-3";
				samsung,pin-function = <0x04>;
				samsung,pin-pud = <0x00>;
				samsung,pin-drv = <0x00>;
			};

			cam-i2c1-bus-pins {
				samsung,pins = "gpf0-2", "gpf0-3";
				samsung,pin-function = <0x02>;
				samsung,pin-pud = <0x03>;
				samsung,pin-drv = <0x00>;
			};

			cam-i2c0-bus-pins {
				samsung,pins = "gpf0-0", "gpf0-1";
				samsung,pin-function = <0x02>;
				samsung,pin-pud = <0x03>;
				samsung,pin-drv = <0x00>;
			};

			cam-spi0-bus-pins {
				samsung,pins = "gpf1-0", "gpf1-1", "gpf1-2", "gpf1-3";
				samsung,pin-function = <0x02>;
				samsung,pin-pud = <0x00>;
				samsung,pin-drv = <0x00>;
			};

			cam-bayrgb-bus-pins {
				samsung,pins = "gpg0-0", "gpg0-1", "gpg0-2", "gpg0-3", "gpg0-4", "gpg0-5", "gpg0-6", "gpg0-7", "gpg1-0", "gpg1-1", "gpg1-2", "gpg1-3", "gpg1-4", "gpg1-5", "gpg1-6", "gpg1-7", "gpg2-0", "gpg2-1";
				samsung,pin-function = <0x02>;
				samsung,pin-pud = <0x00>;
				samsung,pin-drv = <0x00>;
			};

			cam-port-a-pins {
				samsung,pins = "gph0-0", "gph0-1", "gph0-2", "gph0-3", "gph1-0", "gph1-1", "gph1-2", "gph1-3", "gph1-4", "gph1-5", "gph1-6", "gph1-7";
				samsung,pin-function = <0x02>;
				samsung,pin-pud = <0x00>;
				samsung,pin-drv = <0x00>;
			};
		};

		pinctrl@10d10000 {
			compatible = "samsung,exynos5250-pinctrl";
			reg = <0x10d10000 0x1000>;
			interrupts = <0x00 0x32 0x04>;

			gpv0-gpio-bank {
				gpio-controller;
				#gpio-cells = <0x02>;
				interrupt-controller;
				#interrupt-cells = <0x02>;
			};

			gpv1-gpio-bank {
				gpio-controller;
				#gpio-cells = <0x02>;
				interrupt-controller;
				#interrupt-cells = <0x02>;
			};

			gpv2-gpio-bank {
				gpio-controller;
				#gpio-cells = <0x02>;
				interrupt-controller;
				#interrupt-cells = <0x02>;
			};

			gpv3-gpio-bank {
				gpio-controller;
				#gpio-cells = <0x02>;
				interrupt-controller;
				#interrupt-cells = <0x02>;
			};

			gpv4-gpio-bank {
				gpio-controller;
				#gpio-cells = <0x02>;
				interrupt-controller;
				#interrupt-cells = <0x02>;
			};

			c2c-rxd-pins {
				samsung,pins = "gpv0-0", "gpv0-1", "gpv0-2", "gpv0-3", "gpv0-4", "gpv0-5", "gpv0-6", "gpv0-7", "gpv1-0", "gpv1-1", "gpv1-2", "gpv1-3", "gpv1-4", "gpv1-5", "gpv1-6", "gpv1-7";
				samsung,pin-function = <0x02>;
				samsung,pin-pud = <0x00>;
				samsung,pin-drv = <0x00>;
			};

			c2c-txd-pins {
				samsung,pins = "gpv2-0", "gpv2-1", "gpv2-2", "gpv2-3", "gpv2-4", "gpv2-5", "gpv2-6", "gpv2-7", "gpv3-0", "gpv3-1", "gpv3-2", "gpv3-3", "gpv3-4", "gpv3-5", "gpv3-6", "gpv3-7";
				samsung,pin-function = <0x02>;
				samsung,pin-pud = <0x00>;
				samsung,pin-drv = <0x00>;
			};
		};

		pinctrl@3860000 {
			compatible = "samsung,exynos5250-pinctrl";
			reg = <0x3860000 0x1000>;
			interrupts = <0x00 0x2f 0x04>;
			power-domains = <0x1a>;

			gpz-gpio-bank {
				gpio-controller;
				#gpio-cells = <0x02>;
				interrupt-controller;
				#interrupt-cells = <0x02>;
			};

			i2s0-bus-pins {
				samsung,pins = "gpz-0", "gpz-1", "gpz-2", "gpz-3", "gpz-4", "gpz-5", "gpz-6";
				samsung,pin-function = <0x02>;
				samsung,pin-pud = <0x00>;
				samsung,pin-drv = <0x02>;
				phandle = <0x35>;
			};
		};

		system-controller@10040000 {
			compatible = "samsung,exynos5250-pmu", "simple-mfd", "syscon";
			reg = <0x10040000 0x5000>;
			clock-names = "clkout16";
			clocks = <0x02 0x01>;
			#clock-cells = <0x01>;
			interrupt-controller;
			#interrupt-cells = <0x03>;
			interrupt-parent = <0x01>;
			phandle = <0x14>;

			dp-phy {
				compatible = "samsung,exynos5250-dp-video-phy";
				#phy-cells = <0x00>;
				phandle = <0x18>;
			};

			mipi-phy {
				compatible = "samsung,s5pv210-mipi-video-phy";
				#phy-cells = <0x01>;
				phandle = <0x49>;
			};

			syscon-poweroff {
				compatible = "syscon-poweroff";
				regmap = <0x14>;
				offset = <0x330c>;
				mask = <0x5200>;
			};

			syscon-reboot {
				compatible = "syscon-reboot";
				regmap = <0x14>;
				offset = <0x400>;
				mask = <0x01>;
			};
		};

		watchdog@101d0000 {
			compatible = "samsung,exynos5250-wdt";
			reg = <0x101d0000 0x100>;
			interrupts = <0x00 0x2a 0x04>;
			clocks = <0x02 0x150>;
			clock-names = "watchdog";
			samsung,syscon-phandle = <0x14>;
		};

		codec@11000000 {
			compatible = "samsung,mfc-v6";
			reg = <0x11000000 0x10000>;
			interrupts = <0x00 0x60 0x04>;
			power-domains = <0x1c>;
			clocks = <0x02 0x10a>;
			clock-names = "mfc";
			iommus = <0x1d 0x1e>;
			iommu-names = "left", "right";
		};

		rotator@11c00000 {
			compatible = "samsung,exynos5250-rotator";
			reg = <0x11c00000 0x64>;
			interrupts = <0x00 0x54 0x04>;
			clocks = <0x02 0x10d>;
			clock-names = "rotator";
			iommus = <0x1f>;
		};

		gpu@11800000 {
			compatible = "samsung,exynos5250-mali", "arm,mali-t604";
			reg = <0x11800000 0x5000>;
			interrupts = <0x00 0x76 0x04 0x00 0x77 0x04 0x00 0x75 0x04>;
			interrupt-names = "job", "mmu", "gpu";
			clocks = <0x02 0x15d>;
			clock-names = "core";
			operating-points-v2 = <0x20>;
			power-domains = <0x21>;
			status = "okay";
			mali-supply = <0x22>;

			opp-table {
				compatible = "operating-points-v2";
				phandle = <0x20>;

				opp-100000000 {
					opp-hz = <0x00 0x5f5e100>;
					opp-microvolt = <0xe1d48>;
				};

				opp-160000000 {
					opp-hz = <0x00 0x9896800>;
					opp-microvolt = <0xe1d48>;
				};

				opp-266000000 {
					opp-hz = <0x00 0xfdad680>;
					opp-microvolt = <0xfa3e8>;
				};

				opp-350000000 {
					opp-hz = <0x00 0x14dc9380>;
					opp-microvolt = <0x106738>;
				};

				opp-400000000 {
					opp-hz = <0x00 0x17d78400>;
					opp-microvolt = <0x112a88>;
				};

				opp-450000000 {
					opp-hz = <0x00 0x1ad27480>;
					opp-microvolt = <0x118c30>;
				};

				opp-533000000 {
					opp-hz = <0x00 0x1fc4ef40>;
					opp-microvolt = <0x1312d0>;
				};
			};
		};

		tmu@10060000 {
			compatible = "samsung,exynos5250-tmu";
			reg = <0x10060000 0x100>;
			interrupts = <0x00 0x41 0x04>;
			clocks = <0x02 0x152>;
			clock-names = "tmu_apbif";
			#thermal-sensor-cells = <0x00>;
			phandle = <0x4e>;
		};

		sata@122f0000 {
			compatible = "snps,dwc-ahci";
			reg = <0x122f0000 0x1ff>;
			interrupts = <0x00 0x73 0x04>;
			clocks = <0x02 0x115 0x02 0x8f>;
			clock-names = "sata", "pclk";
			phys = <0x23>;
			phy-names = "sata-phy";
			ports-implemented = <0x01>;
			status = "okay";
		};

		sata-phy@12170000 {
			compatible = "samsung,exynos5250-sata-phy";
			reg = <0x12170000 0x1ff>;
			clocks = <0x02 0x11f>;
			clock-names = "sata_phyctrl";
			#phy-cells = <0x00>;
			samsung,syscon-phandle = <0x14>;
			status = "okay";
			samsung,exynos-sataphy-i2c-phandle = <0x24>;
			phandle = <0x23>;
		};

		i2c@12ca0000 {
			compatible = "samsung,s3c2440-i2c";
			reg = <0x12ca0000 0x100>;
			interrupts = <0x00 0x3c 0x04>;
			#address-cells = <0x01>;
			#size-cells = <0x00>;
			clocks = <0x02 0x12a>;
			clock-names = "i2c";
			pinctrl-names = "default";
			pinctrl-0 = <0x25>;
			status = "disabled";
		};

		i2c@12cb0000 {
			compatible = "samsung,s3c2440-i2c";
			reg = <0x12cb0000 0x100>;
			interrupts = <0x00 0x3d 0x04>;
			#address-cells = <0x01>;
			#size-cells = <0x00>;
			clocks = <0x02 0x12b>;
			clock-names = "i2c";
			pinctrl-names = "default";
			pinctrl-0 = <0x26>;
			status = "disabled";
		};

		i2c@12cc0000 {
			compatible = "samsung,s3c2440-i2c";
			reg = <0x12cc0000 0x100>;
			interrupts = <0x00 0x3e 0x04>;
			#address-cells = <0x01>;
			#size-cells = <0x00>;
			clocks = <0x02 0x12c>;
			clock-names = "i2c";
			pinctrl-names = "default";
			pinctrl-0 = <0x27>;
			status = "disabled";
		};

		i2c@12cd0000 {
			compatible = "samsung,s3c2440-i2c";
			reg = <0x12cd0000 0x100>;
			interrupts = <0x00 0x3f 0x04>;
			#address-cells = <0x01>;
			#size-cells = <0x00>;
			clocks = <0x02 0x12d>;
			clock-names = "i2c";
			pinctrl-names = "default";
			pinctrl-0 = <0x28>;
			status = "disabled";
		};

		i2c@12ce0000 {
			compatible = "samsung,s3c2440-hdmiphy-i2c";
			reg = <0x12ce0000 0x1000>;
			interrupts = <0x00 0x40 0x04>;
			#address-cells = <0x01>;
			#size-cells = <0x00>;
			clocks = <0x02 0x12e>;
			clock-names = "i2c";
			status = "okay";
			samsung,i2c-sda-delay = <0x64>;
			samsung,i2c-max-bus-freq = <0x101d0>;

			hdmi-phy@38 {
				compatible = "samsung,exynos4212-hdmiphy";
				reg = <0x38>;
				phandle = <0x41>;
			};
		};

		i2c@121d0000 {
			compatible = "samsung,exynos5-sata-phy-i2c";
			reg = <0x121d0000 0x100>;
			#address-cells = <0x01>;
			#size-cells = <0x00>;
			clocks = <0x02 0x120>;
			clock-names = "i2c";
			status = "okay";
			samsung,i2c-sda-delay = <0x64>;
			samsung,i2c-max-bus-freq = <0x9c40>;

			sata-phy-i2c@38 {
				compatible = "samsung,exynos-sataphy-i2c";
				reg = <0x38>;
				status = "okay";
				phandle = <0x24>;
			};
		};

		spi@12d20000 {
			compatible = "samsung,exynos4210-spi";
			status = "disabled";
			reg = <0x12d20000 0x100>;
			interrupts = <0x00 0x42 0x04>;
			dmas = <0x03 0x05 0x03 0x04>;
			dma-names = "tx", "rx";
			#address-cells = <0x01>;
			#size-cells = <0x00>;
			clocks = <0x02 0x130 0x02 0x9a>;
			clock-names = "spi", "spi_busclk0";
			pinctrl-names = "default";
			pinctrl-0 = <0x29>;
			fifo-depth = <0x100>;
		};

		spi@12d30000 {
			compatible = "samsung,exynos4210-spi";
			status = "disabled";
			reg = <0x12d30000 0x100>;
			interrupts = <0x00 0x43 0x04>;
			dmas = <0x04 0x05 0x04 0x04>;
			dma-names = "tx", "rx";
			#address-cells = <0x01>;
			#size-cells = <0x00>;
			clocks = <0x02 0x131 0x02 0x9b>;
			clock-names = "spi", "spi_busclk0";
			pinctrl-names = "default";
			pinctrl-0 = <0x2a>;
			fifo-depth = <0x40>;
		};

		spi@12d40000 {
			compatible = "samsung,exynos4210-spi";
			status = "disabled";
			reg = <0x12d40000 0x100>;
			interrupts = <0x00 0x44 0x04>;
			dmas = <0x03 0x07 0x03 0x06>;
			dma-names = "tx", "rx";
			#address-cells = <0x01>;
			#size-cells = <0x00>;
			clocks = <0x02 0x132 0x02 0x9c>;
			clock-names = "spi", "spi_busclk0";
			pinctrl-names = "default";
			pinctrl-0 = <0x2b>;
			fifo-depth = <0x40>;
		};

		mmc@12200000 {
			compatible = "samsung,exynos5250-dw-mshc";
			interrupts = <0x00 0x4b 0x04>;
			#address-cells = <0x01>;
			#size-cells = <0x00>;
			reg = <0x12200000 0x1000>;
			clocks = <0x02 0x118 0x02 0x8b>;
			clock-names = "biu", "ciu";
			fifo-depth = <0x80>;
			status = "okay";
			broken-cd;
			card-detect-delay = <0xc8>;
			samsung,dw-mshc-ciu-div = <0x03>;
			samsung,dw-mshc-sdr-timing = <0x02 0x03>;
			samsung,dw-mshc-ddr-timing = <0x01 0x02>;
			vmmc-supply = <0x2c>;
			pinctrl-names = "default";
			pinctrl-0 = <0x2d 0x2e 0x2f 0x30>;
			bus-width = <0x08>;
			cap-mmc-highspeed;
			mmc-ddr-1_8v;
		};

		mmc@12210000 {
			compatible = "samsung,exynos5250-dw-mshc";
			interrupts = <0x00 0x4c 0x04>;
			#address-cells = <0x01>;
			#size-cells = <0x00>;
			reg = <0x12210000 0x1000>;
			clocks = <0x02 0x119 0x02 0x8c>;
			clock-names = "biu", "ciu";
			fifo-depth = <0x80>;
			status = "disabled";
		};

		mmc@12220000 {
			compatible = "samsung,exynos5250-dw-mshc";
			interrupts = <0x00 0x4d 0x04>;
			#address-cells = <0x01>;
			#size-cells = <0x00>;
			reg = <0x12220000 0x1000>;
			clocks = <0x02 0x11a 0x02 0x8d>;
			clock-names = "biu", "ciu";
			fifo-depth = <0x80>;
			status = "okay";
			card-detect-delay = <0xc8>;
			samsung,dw-mshc-ciu-div = <0x03>;
			samsung,dw-mshc-sdr-timing = <0x02 0x03>;
			samsung,dw-mshc-ddr-timing = <0x01 0x02>;
			vmmc-supply = <0x2c>;
			pinctrl-names = "default";
			pinctrl-0 = <0x31 0x32 0x33 0x34>;
			bus-width = <0x04>;
			disable-wp;
			cap-sd-highspeed;
		};

		mmc@12230000 {
			compatible = "samsung,exynos5250-dw-mshc";
			reg = <0x12230000 0x1000>;
			interrupts = <0x00 0x4e 0x04>;
			#address-cells = <0x01>;
			#size-cells = <0x00>;
			clocks = <0x02 0x11b 0x02 0x8e>;
			clock-names = "biu", "ciu";
			fifo-depth = <0x80>;
			status = "disabled";
		};

		i2s@3830000 {
			compatible = "samsung,s5pv210-i2s";
			status = "okay";
			reg = <0x3830000 0x100>;
			dmas = <0x03 0x0a 0x03 0x09 0x03 0x08>;
			dma-names = "tx", "rx", "tx-sec";
			clocks = <0x1b 0x06 0x1b 0x06 0x1b 0x07>;
			clock-names = "iis", "i2s_opclk0", "i2s_opclk1";
			samsung,idma-addr = <0x3000000>;
			pinctrl-names = "default";
			pinctrl-0 = <0x35>;
			power-domains = <0x1a>;
			#clock-cells = <0x01>;
			#sound-dai-cells = <0x01>;
			assigned-clocks = <0x11 0x01>;
			assigned-clock-parents = <0x1b 0x06>;
			phandle = <0x11>;
		};

		i2s@12d60000 {
			compatible = "samsung,s3c6410-i2s";
			status = "disabled";
			reg = <0x12d60000 0x100>;
			dmas = <0x04 0x0c 0x04 0x0b>;
			dma-names = "tx", "rx";
			clocks = <0x02 0x133 0x02 0x9d>;
			clock-names = "iis", "i2s_opclk0";
			pinctrl-names = "default";
			pinctrl-0 = <0x36>;
			power-domains = <0x1a>;
			#sound-dai-cells = <0x01>;
		};

		i2s@12d70000 {
			compatible = "samsung,s3c6410-i2s";
			status = "disabled";
			reg = <0x12d70000 0x100>;
			dmas = <0x03 0x0c 0x03 0x0b>;
			dma-names = "tx", "rx";
			clocks = <0x02 0x134 0x02 0x9e>;
			clock-names = "iis", "i2s_opclk0";
			pinctrl-names = "default";
			pinctrl-0 = <0x37>;
			power-domains = <0x1a>;
			#sound-dai-cells = <0x01>;
		};

		usb@12000000 {
			compatible = "samsung,exynos5250-dwusb3";
			clocks = <0x02 0x11e>;
			clock-names = "usbdrd30";
			#address-cells = <0x01>;
			#size-cells = <0x01>;
			ranges = <0x00 0x12000000 0x10000>;
			vdd10-supply = <0x38>;
			vdd33-supply = <0x39>;

			usb@0 {
				compatible = "snps,dwc3";
				reg = <0x00 0x10000>;
				interrupts = <0x00 0x48 0x04>;
				phys = <0x3a 0x00 0x3a 0x01>;
				phy-names = "usb2-phy", "usb3-phy";
			};
		};

		phy@12100000 {
			compatible = "samsung,exynos5250-usbdrd-phy";
			reg = <0x12100000 0x100>;
			clocks = <0x02 0x11e 0x02 0x01>;
			clock-names = "phy", "ref";
			samsung,pmu-syscon = <0x14>;
			#phy-cells = <0x01>;
			phandle = <0x3a>;
		};

		usb@12110000 {
			compatible = "samsung,exynos4210-ehci";
			reg = <0x12110000 0x100>;
			interrupts = <0x00 0x47 0x04>;
			clocks = <0x02 0x11d>;
			clock-names = "usbhost";
			phys = <0x3b 0x01>;
			phy-names = "host";
		};

		usb@12120000 {
			compatible = "samsung,exynos4210-ohci";
			reg = <0x12120000 0x100>;
			interrupts = <0x00 0x47 0x04>;
			clocks = <0x02 0x11d>;
			clock-names = "usbhost";
			phys = <0x3b 0x01>;
			phy-names = "host";
		};

		phy@12130000 {
			compatible = "samsung,exynos5250-usb2-phy";
			reg = <0x12130000 0x100>;
			clocks = <0x02 0x11d 0x02 0x01>;
			clock-names = "phy", "ref";
			#phy-cells = <0x01>;
			samsung,sysreg-phandle = <0x05>;
			samsung,pmureg-phandle = <0x14>;
			phandle = <0x3b>;
		};

		dma-controller@121a0000 {
			compatible = "arm,pl330", "arm,primecell";
			reg = <0x121a0000 0x1000>;
			interrupts = <0x00 0x22 0x04>;
			clocks = <0x02 0x113>;
			clock-names = "apb_pclk";
			#dma-cells = <0x01>;
			phandle = <0x03>;
		};

		dma-controller@121b0000 {
			compatible = "arm,pl330", "arm,primecell";
			reg = <0x121b0000 0x1000>;
			interrupts = <0x00 0x23 0x04>;
			clocks = <0x02 0x114>;
			clock-names = "apb_pclk";
			#dma-cells = <0x01>;
			phandle = <0x04>;
		};

		dma-controller@10800000 {
			compatible = "arm,pl330", "arm,primecell";
			reg = <0x10800000 0x1000>;
			interrupts = <0x00 0x21 0x04>;
			clocks = <0x02 0x15a>;
			clock-names = "apb_pclk";
			#dma-cells = <0x01>;
		};

		dma-controller@11c10000 {
			compatible = "arm,pl330", "arm,primecell";
			reg = <0x11c10000 0x1000>;
			interrupts = <0x00 0x7c 0x04>;
			clocks = <0x02 0x10f>;
			clock-names = "apb_pclk";
			#dma-cells = <0x01>;
		};

		gsc@13e00000 {
			compatible = "samsung,exynos5250-gsc", "samsung,exynos5-gsc";
			reg = <0x13e00000 0x1000>;
			interrupts = <0x00 0x55 0x04>;
			power-domains = <0x3c>;
			clocks = <0x02 0x100>;
			clock-names = "gscl";
			iommus = <0x3d>;
		};

		gsc@13e10000 {
			compatible = "samsung,exynos5250-gsc", "samsung,exynos5-gsc";
			reg = <0x13e10000 0x1000>;
			interrupts = <0x00 0x56 0x04>;
			power-domains = <0x3c>;
			clocks = <0x02 0x101>;
			clock-names = "gscl";
			iommus = <0x3e>;
		};

		gsc@13e20000 {
			compatible = "samsung,exynos5250-gsc", "samsung,exynos5-gsc";
			reg = <0x13e20000 0x1000>;
			interrupts = <0x00 0x57 0x04>;
			power-domains = <0x3c>;
			clocks = <0x02 0x102>;
			clock-names = "gscl";
			iommus = <0x3f>;
		};

		gsc@13e30000 {
			compatible = "samsung,exynos5250-gsc", "samsung,exynos5-gsc";
			reg = <0x13e30000 0x1000>;
			interrupts = <0x00 0x58 0x04>;
			power-domains = <0x3c>;
			clocks = <0x02 0x103>;
			clock-names = "gscl";
			iommus = <0x40>;
		};

		hdmi@14530000 {
			compatible = "samsung,exynos4212-hdmi";
			reg = <0x14530000 0x70000>;
			power-domains = <0x16>;
			interrupts = <0x00 0x5f 0x04>;
			clocks = <0x02 0x158 0x02 0x88 0x02 0x89 0x02 0x9f 0x02 0x400>;
			clock-names = "hdmi", "sclk_hdmi", "sclk_pixel", "sclk_hdmiphy", "mout_hdmi";
			samsung,syscon-phandle = <0x14>;
			phy = <0x41>;
			#sound-dai-cells = <0x00>;
			status = "okay";
			pinctrl-names = "default";
			pinctrl-0 = <0x42>;
			ddc = <0x43>;
			hpd-gpios = <0x07 0x07 0x00>;
			vdd_osc-supply = <0x44>;
			vdd_pll-supply = <0x45>;
			vdd-supply = <0x45>;
			phandle = <0x46>;
		};

		cec@101b0000 {
			compatible = "samsung,s5p-cec";
			reg = <0x101b0000 0x200>;
			interrupts = <0x00 0x72 0x04>;
			clocks = <0x02 0x14e>;
			clock-names = "hdmicec";
			samsung,syscon-phandle = <0x14>;
			hdmi-phandle = <0x46>;
			pinctrl-names = "default";
			pinctrl-0 = <0x47>;
			status = "disabled";
		};

		mixer@14450000 {
			compatible = "samsung,exynos5250-mixer";
			reg = <0x14450000 0x10000>;
			power-domains = <0x16>;
			interrupts = <0x00 0x5e 0x04>;
			clocks = <0x02 0x157 0x02 0x158 0x02 0x88>;
			clock-names = "mixer", "hdmi", "sclk_hdmi";
			iommus = <0x48>;
			status = "okay";
		};

		dsi@14500000 {
			compatible = "samsung,exynos4210-mipi-dsi";
			reg = <0x14500000 0x10000>;
			interrupts = <0x00 0x52 0x04>;
			samsung,power-domain = <0x16>;
			phys = <0x49 0x03>;
			phy-names = "dsim";
			clocks = <0x02 0x155 0x02 0x86>;
			clock-names = "bus_clk", "sclk_mipi";
			status = "okay";
			#address-cells = <0x01>;
			#size-cells = <0x00>;
			vddcore-supply = <0x45>;
			vddio-supply = <0x44>;
			samsung,pll-clock-frequency = <0x16e3600>;
			samsung,burst-clock-frequency = <0x1312d000>;
			samsung,esc-clock-frequency = <0x989680>;

			bridge@0 {
				reg = <0x00>;
				compatible = "toshiba,tc358764";
				vddc-supply = <0x4a>;
				vddio-supply = <0x4b>;
				vddlvds-supply = <0x4c>;
				reset-gpios = <0x0c 0x06 0x01>;

				ports {
					#address-cells = <0x01>;
					#size-cells = <0x00>;

					port@1 {
						reg = <0x01>;

						endpoint {
							remote-endpoint = <0x4d>;
							phandle = <0x58>;
						};
					};
				};
			};
		};

		adc@12d10000 {
			compatible = "samsung,exynos-adc-v1";
			reg = <0x12d10000 0x100>;
			interrupts = <0x00 0x6a 0x04>;
			clocks = <0x02 0x12f>;
			clock-names = "adc";
			#io-channel-cells = <0x01>;
			samsung,syscon-phandle = <0x14>;
			status = "disabled";
		};

		sysmmu@10a60000 {
			compatible = "samsung,exynos-sysmmu";
			reg = <0x10a60000 0x1000>;
			interrupt-parent = <0x15>;
			interrupts = <0x18 0x05>;
			clock-names = "sysmmu", "master";
			clocks = <0x02 0x160 0x02 0x159>;
			#iommu-cells = <0x00>;
			phandle = <0x19>;
		};

		sysmmu@11200000 {
			compatible = "samsung,exynos-sysmmu";
			reg = <0x11200000 0x1000>;
			interrupt-parent = <0x15>;
			interrupts = <0x06 0x02>;
			power-domains = <0x1c>;
			clock-names = "sysmmu", "master";
			clocks = <0x02 0x10c 0x02 0x10a>;
			#iommu-cells = <0x00>;
			phandle = <0x1e>;
		};

		sysmmu@11210000 {
			compatible = "samsung,exynos-sysmmu";
			reg = <0x11210000 0x1000>;
			interrupt-parent = <0x15>;
			interrupts = <0x08 0x05>;
			power-domains = <0x1c>;
			clock-names = "sysmmu", "master";
			clocks = <0x02 0x10b 0x02 0x10a>;
			#iommu-cells = <0x00>;
			phandle = <0x1d>;
		};

		sysmmu@11d40000 {
			compatible = "samsung,exynos-sysmmu";
			reg = <0x11d40000 0x1000>;
			interrupt-parent = <0x15>;
			interrupts = <0x04 0x00>;
			clock-names = "sysmmu", "master";
			clocks = <0x02 0x110 0x02 0x10d>;
			#iommu-cells = <0x00>;
			phandle = <0x1f>;
		};

		sysmmu@11f20000 {
			compatible = "samsung,exynos-sysmmu";
			reg = <0x11f20000 0x1000>;
			interrupt-parent = <0x15>;
			interrupts = <0x04 0x02>;
			power-domains = <0x3c>;
			clock-names = "sysmmu", "master";
			clocks = <0x02 0x111 0x02 0x10e>;
			#iommu-cells = <0x00>;
		};

		sysmmu@13260000 {
			compatible = "samsung,exynos-sysmmu";
			reg = <0x13260000 0x1000>;
			interrupt-parent = <0x15>;
			interrupts = <0x0a 0x06>;
			clock-names = "sysmmu";
			clocks = <0x02 0x161>;
			#iommu-cells = <0x00>;
		};

		sysmmu@13270000 {
			compatible = "samsung,exynos-sysmmu";
			reg = <0x13270000 0x1000>;
			interrupt-parent = <0x15>;
			interrupts = <0x0b 0x06>;
			clock-names = "sysmmu";
			clocks = <0x02 0x162>;
			#iommu-cells = <0x00>;
		};

		sysmmu@132a0000 {
			compatible = "samsung,exynos-sysmmu";
			reg = <0x132a0000 0x1000>;
			interrupt-parent = <0x15>;
			interrupts = <0x05 0x00>;
			clock-names = "sysmmu";
			clocks = <0x02 0x165>;
			#iommu-cells = <0x00>;
		};

		sysmmu@13280000 {
			compatible = "samsung,exynos-sysmmu";
			reg = <0x13280000 0x1000>;
			interrupt-parent = <0x15>;
			interrupts = <0x05 0x02>;
			clock-names = "sysmmu";
			clocks = <0x02 0x163>;
			#iommu-cells = <0x00>;
		};

		sysmmu@13290000 {
			compatible = "samsung,exynos-sysmmu";
			reg = <0x13290000 0x1000>;
			interrupt-parent = <0x15>;
			interrupts = <0x03 0x06>;
			clock-names = "sysmmu";
			clocks = <0x02 0x164>;
			#iommu-cells = <0x00>;
		};

		sysmmu@132b0000 {
			compatible = "samsung,exynos-sysmmu";
			reg = <0x132b0000 0x1000>;
			interrupt-parent = <0x15>;
			interrupts = <0x05 0x04>;
			clock-names = "sysmmu";
			clocks = <0x02 0x166>;
			#iommu-cells = <0x00>;
		};

		sysmmu@132c0000 {
			compatible = "samsung,exynos-sysmmu";
			reg = <0x132c0000 0x1000>;
			interrupt-parent = <0x15>;
			interrupts = <0x0b 0x00>;
			clock-names = "sysmmu";
			clocks = <0x02 0x167>;
			#iommu-cells = <0x00>;
		};

		sysmmu@132d0000 {
			compatible = "samsung,exynos-sysmmu";
			reg = <0x132d0000 0x1000>;
			interrupt-parent = <0x15>;
			interrupts = <0x0a 0x04>;
			clock-names = "sysmmu";
			clocks = <0x02 0x168>;
			#iommu-cells = <0x00>;
		};

		sysmmu@132e0000 {
			compatible = "samsung,exynos-sysmmu";
			reg = <0x132e0000 0x1000>;
			interrupt-parent = <0x15>;
			interrupts = <0x09 0x04>;
			clock-names = "sysmmu";
			clocks = <0x02 0x169>;
			#iommu-cells = <0x00>;
		};

		sysmmu@132f0000 {
			compatible = "samsung,exynos-sysmmu";
			reg = <0x132f0000 0x1000>;
			interrupt-parent = <0x15>;
			interrupts = <0x05 0x06>;
			clock-names = "sysmmu";
			clocks = <0x02 0x16a>;
			#iommu-cells = <0x00>;
		};

		sysmmu@13c40000 {
			compatible = "samsung,exynos-sysmmu";
			reg = <0x13c40000 0x1000>;
			interrupt-parent = <0x15>;
			interrupts = <0x03 0x04>;
			power-domains = <0x3c>;
			clock-names = "sysmmu", "master";
			clocks = <0x02 0x16b 0x02 0x16d>;
			#iommu-cells = <0x00>;
		};

		sysmmu@13c50000 {
			compatible = "samsung,exynos-sysmmu";
			reg = <0x13c50000 0x1000>;
			interrupt-parent = <0x15>;
			interrupts = <0x18 0x01>;
			power-domains = <0x3c>;
			clock-names = "sysmmu", "master";
			clocks = <0x02 0x16c 0x02 0x16d>;
			#iommu-cells = <0x00>;
		};

		sysmmu@13e80000 {
			compatible = "samsung,exynos-sysmmu";
			reg = <0x13e80000 0x1000>;
			interrupt-parent = <0x15>;
			interrupts = <0x02 0x00>;
			power-domains = <0x3c>;
			clock-names = "sysmmu", "master";
			clocks = <0x02 0x106 0x02 0x100>;
			#iommu-cells = <0x00>;
			phandle = <0x3d>;
		};

		sysmmu@13e90000 {
			compatible = "samsung,exynos-sysmmu";
			reg = <0x13e90000 0x1000>;
			interrupt-parent = <0x15>;
			interrupts = <0x02 0x02>;
			power-domains = <0x3c>;
			clock-names = "sysmmu", "master";
			clocks = <0x02 0x107 0x02 0x101>;
			#iommu-cells = <0x00>;
			phandle = <0x3e>;
		};

		sysmmu@13ea0000 {
			compatible = "samsung,exynos-sysmmu";
			reg = <0x13ea0000 0x1000>;
			interrupt-parent = <0x15>;
			interrupts = <0x02 0x04>;
			power-domains = <0x3c>;
			clock-names = "sysmmu", "master";
			clocks = <0x02 0x108 0x02 0x102>;
			#iommu-cells = <0x00>;
			phandle = <0x3f>;
		};

		sysmmu@13eb0000 {
			compatible = "samsung,exynos-sysmmu";
			reg = <0x13eb0000 0x1000>;
			interrupt-parent = <0x15>;
			interrupts = <0x02 0x06>;
			power-domains = <0x3c>;
			clock-names = "sysmmu", "master";
			clocks = <0x02 0x109 0x02 0x103>;
			#iommu-cells = <0x00>;
			phandle = <0x40>;
		};

		sysmmu@14640000 {
			compatible = "samsung,exynos-sysmmu";
			reg = <0x14640000 0x1000>;
			interrupt-parent = <0x15>;
			interrupts = <0x03 0x02>;
			power-domains = <0x16>;
			clock-names = "sysmmu", "master";
			clocks = <0x02 0x15f 0x02 0x153>;
			#iommu-cells = <0x00>;
			phandle = <0x17>;
		};

		sysmmu@14650000 {
			compatible = "samsung,exynos-sysmmu";
			reg = <0x14650000 0x1000>;
			interrupt-parent = <0x15>;
			interrupts = <0x07 0x04>;
			power-domains = <0x16>;
			clock-names = "sysmmu", "master";
			clocks = <0x02 0x15e 0x02 0x157>;
			#iommu-cells = <0x00>;
			phandle = <0x48>;
		};
	};

	thermal-zones {

		cpu-thermal {
			thermal-sensors = <0x4e>;
			polling-delay-passive = <0x00>;
			polling-delay = <0x00>;

			trips {

				cpu-alert-0 {
					temperature = <0x11170>;
					hysteresis = <0x2710>;
					type = "active";
					phandle = <0x4f>;
				};

				cpu-alert-1 {
					temperature = <0x17318>;
					hysteresis = <0x2710>;
					type = "active";
					phandle = <0x52>;
				};

				cpu-alert-2 {
					temperature = <0x1adb0>;
					hysteresis = <0x2710>;
					type = "active";
				};

				cpu-crit-0 {
					temperature = <0x1d4c0>;
					hysteresis = <0x00>;
					type = "critical";
				};
			};

			cooling-maps {

				map0 {
					trip = <0x4f>;
					cooling-device = <0x50 0x09 0x09 0x51 0x09 0x09>;
				};

				map1 {
					trip = <0x52>;
					cooling-device = <0x50 0x0f 0x0f 0x51 0x0f 0x0f>;
				};
			};
		};
	};

	cpus {
		#address-cells = <0x01>;
		#size-cells = <0x00>;

		cpu-map {

			cluster0 {

				core0 {
					cpu = <0x50>;
				};

				core1 {
					cpu = <0x51>;
				};
			};
		};

		cpu@0 {
			device_type = "cpu";
			compatible = "arm,cortex-a15";
			reg = <0x00>;
			clocks = <0x02 0x09>;
			clock-names = "cpu";
			operating-points-v2 = <0x53>;
			#cooling-cells = <0x02>;
			cpu0-supply = <0x54>;
			phandle = <0x50>;
		};

		cpu@1 {
			device_type = "cpu";
			compatible = "arm,cortex-a15";
			reg = <0x01>;
			clocks = <0x02 0x09>;
			clock-names = "cpu";
			operating-points-v2 = <0x53>;
			#cooling-cells = <0x02>;
			phandle = <0x51>;
		};
	};

	opp-table-0 {
		compatible = "operating-points-v2";
		opp-shared;
		phandle = <0x53>;

		opp-200000000 {
			opp-hz = <0x00 0xbebc200>;
			opp-microvolt = <0xe1d48>;
			clock-latency-ns = <0x222e0>;
		};

		opp-300000000 {
			opp-hz = <0x00 0x11e1a300>;
			opp-microvolt = <0xe4e1c>;
			clock-latency-ns = <0x222e0>;
		};

		opp-400000000 {
			opp-hz = <0x00 0x17d78400>;
			opp-microvolt = <0xe7ef0>;
			clock-latency-ns = <0x222e0>;
		};

		opp-500000000 {
			opp-hz = <0x00 0x1dcd6500>;
			opp-microvolt = <0xee098>;
			clock-latency-ns = <0x222e0>;
		};

		opp-600000000 {
			opp-hz = <0x00 0x23c34600>;
			opp-microvolt = <0xf4240>;
			clock-latency-ns = <0x222e0>;
		};

		opp-700000000 {
			opp-hz = <0x00 0x29b92700>;
			opp-microvolt = <0xf7314>;
			clock-latency-ns = <0x222e0>;
		};

		opp-800000000 {
			opp-hz = <0x00 0x2faf0800>;
			opp-microvolt = <0xfa3e8>;
			clock-latency-ns = <0x222e0>;
		};

		opp-900000000 {
			opp-hz = <0x00 0x35a4e900>;
			opp-microvolt = <0x100590>;
			clock-latency-ns = <0x222e0>;
		};

		opp-1000000000 {
			opp-hz = <0x00 0x3b9aca00>;
			opp-microvolt = <0x106738>;
			clock-latency-ns = <0x222e0>;
			opp-suspend;
		};

		opp-1100000000 {
			opp-hz = <0x00 0x4190ab00>;
			opp-microvolt = <0x10c8e0>;
			clock-latency-ns = <0x222e0>;
		};

		opp-1200000000 {
			opp-hz = <0x00 0x47868c00>;
			opp-microvolt = <0x112a88>;
			clock-latency-ns = <0x222e0>;
		};

		opp-1300000000 {
			opp-hz = <0x00 0x4d7c6d00>;
			opp-microvolt = <0x118c30>;
			clock-latency-ns = <0x222e0>;
		};

		opp-1400000000 {
			opp-hz = <0x00 0x53724e00>;
			opp-microvolt = <0x124f80>;
			clock-latency-ns = <0x222e0>;
		};

		opp-1500000000 {
			opp-hz = <0x00 0x59682f00>;
			opp-microvolt = <0x12b128>;
			clock-latency-ns = <0x222e0>;
		};

		opp-1600000000 {
			opp-hz = <0x00 0x5f5e1000>;
			opp-microvolt = <0x1312d0>;
			clock-latency-ns = <0x222e0>;
		};

		opp-1700000000 {
			opp-hz = <0x00 0x6553f100>;
			opp-microvolt = <0x13d620>;
			clock-latency-ns = <0x222e0>;
		};
	};

	pmu {
		compatible = "arm,cortex-a15-pmu";
		interrupt-parent = <0x15>;
		interrupts = <0x01 0x02 0x16 0x04>;
	};

	timer {
		compatible = "arm,armv7-timer";
		interrupts = <0x01 0x0d 0xf08 0x01 0x0e 0xf08 0x01 0x0b 0xf08 0x01 0x0a 0xf08>;
		clock-frequency = <0x16e3600>;
	};

	memory@40000000 {
		device_type = "memory";
		reg = <0x40000000 0x80000000>;
	};

	chosen {
		stdout-path = "serial2:115200n8";
	};

	gpio-keys {
		compatible = "gpio-keys";

		key-menu {
			label = "SW-TACT2";
			gpios = <0x55 0x04 0x01>;
			linux,code = <0x8b>;
			wakeup-source;
		};

		key-home {
			label = "SW-TACT3";
			gpios = <0x55 0x05 0x01>;
			linux,code = <0x66>;
			wakeup-source;
		};

		key-up {
			label = "SW-TACT4";
			gpios = <0x55 0x06 0x01>;
			linux,code = <0x67>;
			wakeup-source;
		};

		key-down {
			label = "SW-TACT5";
			gpios = <0x55 0x07 0x01>;
			linux,code = <0x6c>;
			wakeup-source;
		};

		key-back {
			label = "SW-TACT6";
			gpios = <0x0d 0x00 0x01>;
			linux,code = <0x9e>;
			wakeup-source;
		};

		key-wakeup {
			label = "SW-TACT7";
			gpios = <0x0d 0x01 0x01>;
			linux,code = <0x8f>;
			wakeup-source;
		};
	};

	i2c-10 {
		compatible = "i2c-gpio";
		pinctrl-names = "default";
		pinctrl-0 = <0x56>;
		sda-gpios = <0x57 0x06 0x06>;
		scl-gpios = <0x57 0x07 0x06>;
		i2c-gpio,delay-us = <0x02>;
		phandle = <0x43>;
	};

	panel {
		compatible = "boe,hv070wsa-100";
		power-supply = <0x4c>;
		enable-gpios = <0x0c 0x03 0x00>;

		port {

			endpoint {
				remote-endpoint = <0x58>;
				phandle = <0x4d>;
			};
		};
	};

	regulator-0 {
		compatible = "regulator-fixed";
		regulator-name = "MAIN_DC";
		regulator-always-on;
		phandle = <0x09>;
	};

	regulator-1 {
		compatible = "regulator-fixed";
		regulator-name = "VDD_MMC";
		regulator-min-microvolt = <0x2ab980>;
		regulator-max-microvolt = <0x2ab980>;
		regulator-always-on;
		phandle = <0x2c>;
	};

	regulator-2 {
		compatible = "regulator-fixed";
		regulator-name = "hdmi-en";
		regulator-always-on;
	};

	regulator-3 {
		compatible = "regulator-fixed";
		regulator-name = "VCC_1V2";
		regulator-min-microvolt = <0x124f80>;
		regulator-max-microvolt = <0x124f80>;
		regulator-always-on;
		phandle = <0x4a>;
	};

	regulator-4 {
		compatible = "regulator-fixed";
		regulator-name = "VCC_1V8";
		regulator-min-microvolt = <0x1b7740>;
		regulator-max-microvolt = <0x1b7740>;
		regulator-always-on;
		phandle = <0x4b>;
	};

	regulator-5 {
		compatible = "regulator-fixed";
		regulator-name = "VCC_3V3";
		regulator-min-microvolt = <0x325aa0>;
		regulator-max-microvolt = <0x325aa0>;
		regulator-always-on;
		phandle = <0x4c>;
	};

	sound {
		compatible = "samsung,arndale-wm1811";
		samsung,audio-cpu = <0x11>;
		samsung,audio-codec = <0x59>;
	};

	fixed-rate-clocks {

		xxti {
			compatible = "samsung,clock-xxti";
			clock-frequency = <0x16e3600>;
		};
	};

	usb-hub {
		compatible = "smsc,usb3503a";
		reset-gpios = <0x07 0x05 0x01>;
		connect-gpios = <0x0c 0x07 0x00>;
	};
};
